# LPC2103 register map
Series: LPC2000; File version: r4p0
CPU: other r0p0, selectable endian, no FPU, vendor SysTick, 2 interrupt priority bits
Registers are read-write, reset 0x0 unless marked. A register's access mark holds for its fields unless they carry their own. Offsets are from the block's base; [hi:lo] are bit positions; {n}, {i} and the like mark numbered series.

## VIC — Vectored Interrupt Controller
Base 0xFFFFF000
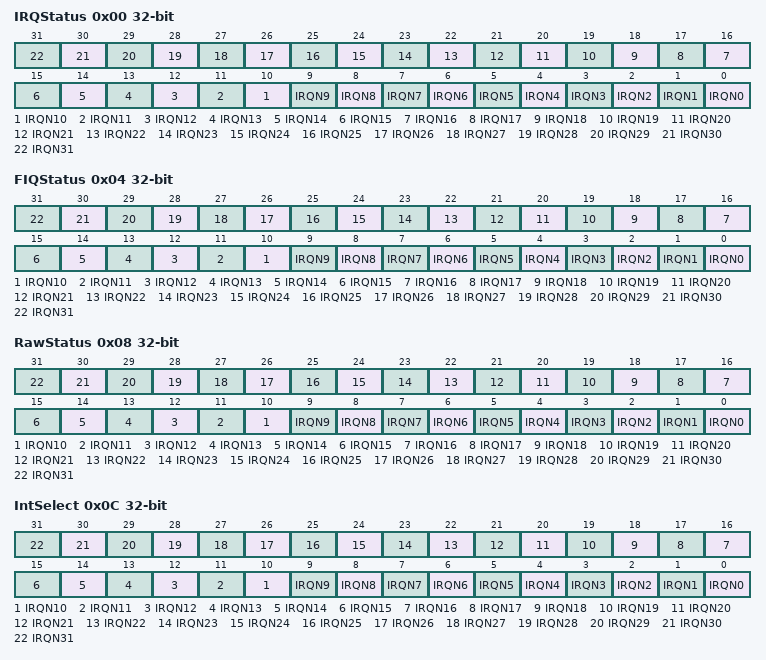
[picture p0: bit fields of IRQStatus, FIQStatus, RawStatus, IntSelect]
0x00 IRQStatus ro
  [n] IRQN{n} (n=0..31) — IRQ {n}
0x04 FIQStatus ro
  [n] IRQN{n} (n=0..31) — IRQ {n}
0x08 RawStatus ro
  [n] IRQN{n} (n=0..31) — IRQ {n}
0x0C IntSelect — Interrupt Path Select Register
  [n] IRQN{n} (n=0..31) — IRQ {n}
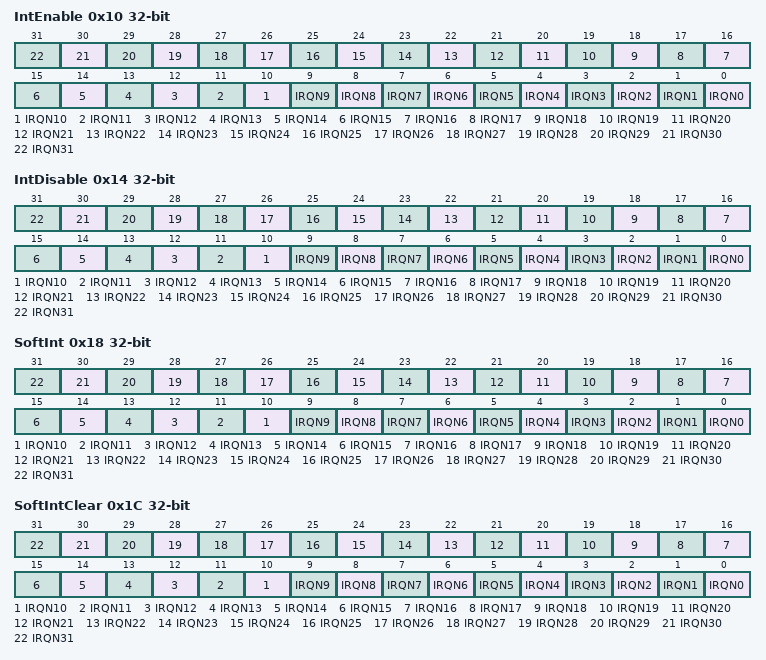
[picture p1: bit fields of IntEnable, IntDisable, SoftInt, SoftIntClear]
0x10 IntEnable — Interrupt Enable Register
  [n] IRQN{n} (n=0..31) — IRQ {n}
0x14 IntDisable wo — Interrupt Disable Register
  [n] IRQN{n} (n=0..31) — IRQ {n}
0x18 SoftInt — Soft Interrupt Register
  [n] IRQN{n} (n=0..31) — IRQ {n}
0x1C SoftIntClear wo — Soft Interrupt Clear Register
  [n] IRQN{n} (n=0..31) — IRQ {n}
0x20 Protection — Protection Level Register
  [0] ACCESS
    0=USER (User and privileged modes can access VIC.); 1=PRIVILEGED (Only privileged mode can access VIC.)
0x30 CurVectAddr write-0-clears — Current Vector Address Register
0x34 DefVectAddr — Default Vector Address Register
{0x100+4i} VectAddr[{i}] (i=0..15) — Vector Address Register
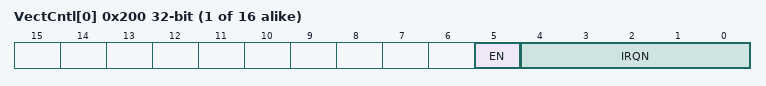
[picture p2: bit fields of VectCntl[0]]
{0x200+4i} VectCntl[{i}] (i=0..15) — Vector Control Register
  [5] EN, [4:0] IRQN

## PCB — Pin Connect Block
Base 0xE002C000
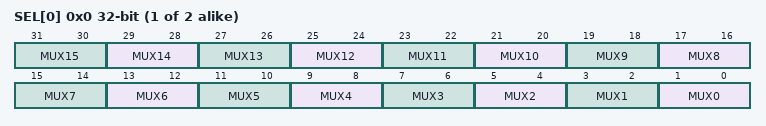
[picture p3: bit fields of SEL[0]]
{0x0+4i} SEL[{i}] (i=0..1)
  [2n+1:2n] MUX{n} (n=0..15)
    0=GPIO; 1=AF1; 2=AF2; 3=AF3

## GPIO0 — General Purpose I/O
Base 0xE0028000
0x00 PIN — GPIO Port Data
0x04 SET — GPIO Port Set Register
0x08 DIR — GPIO Port Direction Register
0x0C CLR — GPIO Port Clear Register

## FIO0 — Fast General Purpose I/O
Base 0x3FFFC000
0x00 DIR — Fast GPIO Port Direction Register
0x10 MASK — Fast GPIO Disable Mask Register
0x14 PIN — Fast GPIO Port Data
0x18 SET — Fast GPIO Port Set Register
0x1C CLR — Fast GPIO Port Clear Register

## UART0 — Universial Asynchronous Receiver/Transceiver
Base 0xE000C000
Same registers: UART1 0xE0010000
0x00 DR — Data Register
  [7:0] DATA
0x00 RBR ro (alternate view of DR) — Receiver Buffer Register
  [7:0] DATA
0x00 THR wo (alternate view of DR) — Transmit Holding Register
  [7:0] DATA
0x00 DLL reset 0x1 (alternate view of DR) — BRG Divisor LSB
  [7:0] DLLSB
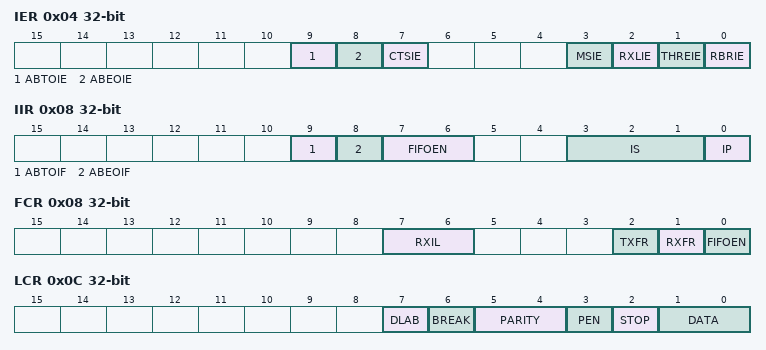
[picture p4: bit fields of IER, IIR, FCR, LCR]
0x04 IER — Interrupt Enable Register
  [9] ABTOIE, [8] ABEOIE, [7] CTSIE, [3] MSIE, [2] RXLIE, [1] THREIE, [0] RBRIE
0x04 DLM (alternate view of IER) — BRG Divider MSB
  [7:0] DLMSB
0x08 IIR ro — Interrupt Identification Register
  [9] ABTOIF
  [8] ABEOIF
  [7:6] FIFOEN
  [3:1] IS
    0=MODEM; 1=THRE; 2=RDA; 3=RLS; 6=CTI
  [0] IP
0x08 FCR wo (alternate view of IIR) — FIFO Control Register
  [7:6] RXIL
    0=1CH; 1=4CH; 2=8CH; 3=14CH
  [2] TXFR
  [1] RXFR
  [0] FIFOEN
0x0C LCR — Line Control Register
  [7] DLAB — Divisor Latch Access Bit
  [6] BREAK — Send BREAK
  [5:4] PARITY — Parity mode
    0=ODD; 1=EVEN; 2=MARK; 3=SPACE
  [3] PEN — Parity Enable
  [2] STOP — Number of STOP bits
    0=1BIT; 1=2BIT
  [1:0] DATA — Number of data bits
    {v}={v+5}BIT (v=0..3)
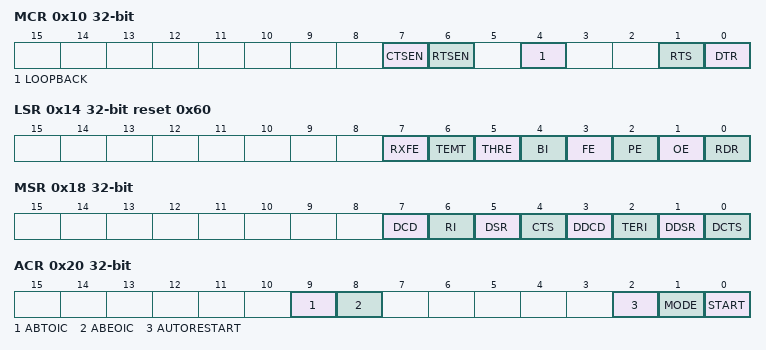
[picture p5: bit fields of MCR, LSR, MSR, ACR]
0x10 MCR — Modem Control Register
  [7] CTSEN — Enable Auto-CTS
  [6] RTSEN — Enable Auto-RTS
  [4] LOOPBACK
  [1] RTS
  [0] DTR
0x14 LSR ro reset 0x60 — Line State Register
  [7] RXFE, [6] TEMT, [5] THRE, [4] BI, [3] FE, [2] PE, [1] OE, [0] RDR
0x18 MSR ro — Modem Status Register
  [7] DCD, [6] RI, [5] DSR, [4] CTS, [3] DDCD, [2] TERI, [1] DDSR, [0] DCTS
0x1C SCR — Scratchpad Register
  [7:0] DATA
0x20 ACR — Autobaud Control Register
  [9] ABTOIC wo write-1-clears — Autobaud Timeout Interrupt Clear
  [8] ABEOIC wo write-1-clears — Autobaud End Interrupt Clear
  [2] AUTORESTART
  [1] MODE
  [0] START
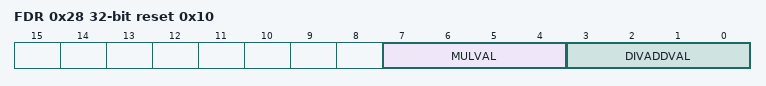
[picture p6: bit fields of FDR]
0x28 FDR reset 0x10 — Fractional Divider Register
  [7:4] MULVAL, [3:0] DIVADDVAL
0x30 TER reset 0x80 — TX Enable Register
  [7] TXEN

## I2C0
Base 0xE001C000
Same registers: I2C1 0xE005C000
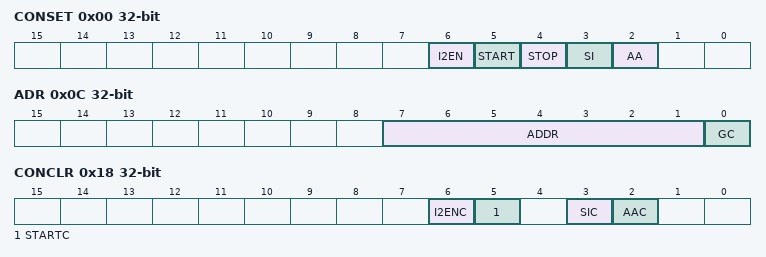
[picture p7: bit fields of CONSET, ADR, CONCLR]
0x00 CONSET write-1-sets — Control Set Register
  [6] I2EN, [5] START, [4] STOP, [3] SI, [2] AA
0x04 STAT ro reset 0xF8 — Status Register
  [7:3] STATUS
    1=TXSTART (START transmitted.); 2=TXRSTART (ReSTART transmitted); 3=TXSLAWACK (TX SLA+W acknowledged); 4=TXSLAWNACK (TX SLA+W negative acknowledged); 5=TXDATAACK (TX Data acknowledged); 6=TXDATANACK (TX Data negative acknowledged); 7=ARBLOST (Arbitration Lost); 8=TXSLARACK (TX SLA+R acknowledged); 9=TXSLARNACK (TX SLA+R negative acknowledged); 10=RXDATAACK (RX Data acknowledged); 11=RXDATANACK (RX Data negative acknowledged); 12=RXSLAW; 13=RXSLAWAL (RX SLA+W losing arbitration); 14=RXGC (RX General Call); 15=RXGCAL (RX General Call losing arbitration); 16=RXSLADACK (SLA mode RX data with acknowledgement); 17=RXSLADNACK (SLA mode RX data with negative acknowledgement); 18=RXGCDACK (GC mode RX data with acknowledgement); 19=RXGCDNACK (GC mode RX data with negative acknowledgement); 20=RXSLASTOP (RX STOP or RESTART amid SLA mode); 21=RXSLAR; 22=RXSLARAL (RX SLA+R losing arbitration); 23=TXSLADACK (SLA mode TX data with acknowledgement); 24=TXSLADNACK (SLA mode TX data with negative acknowledgement); 25=TXSLADLAST (SLA mode TX data with last data); 31=BUSY (I2C block is busy); 0=ERROR (I2C bus error)
0x08 DATA
  [7:0] DATA
0x0C ADR — Slave Address Register
  [7:1] ADDR, [0] GC
0x10 SCL{x} (x=H,L; step 0x4) reset 0x4 — SCL {x} Duty Cycle Register
  [15:0] DUTY
0x18 CONCLR wo write-1-clears — Control Clear Register
  [6] I2ENC, [5] STARTC, [3] SIC, [2] AAC
